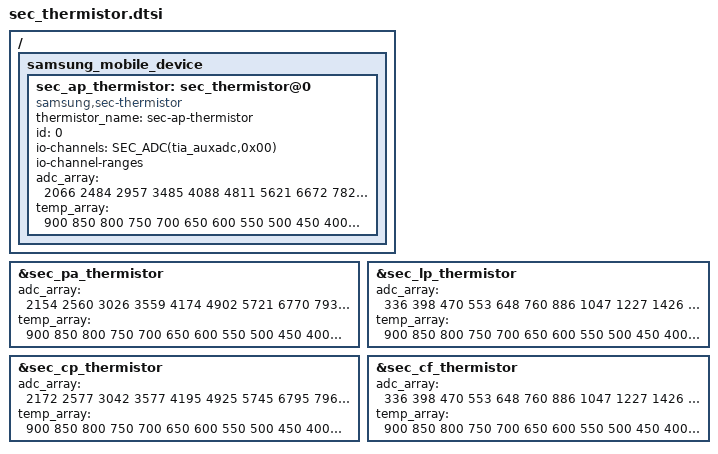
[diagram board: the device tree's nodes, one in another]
/ {
	fragment@smd {
		target-path = "/";
		__overlay__ {
			samsung_mobile_device {
				sec_ap_thermistor: sec_thermistor@0 {
					compatible = "samsung,sec-thermistor";
					status = "okay";
					thermistor_name = "sec-ap-thermistor";
					id = <0>;

					io-channels = SEC_ADC(tia_auxadc,0x00);
					io-channel-names = "ap_therm";
					io-channel-ranges;
				};
			};
		};
	};
};

/* /home/dpi/qb5_8814/workspace/P4_1716/android/kernel/kmodule/sec_pm/sec_thermistor/dts/sec_thermistor_mtk.a25ex_jpn.04.dtsi */
&sec_ap_thermistor {
	adc_array = <2066 2484 2957 3485 4088 4811 5621 6672 7826 9111
				10458 12043 13780 15592 17502 19410 21221 22944 24520 25952
				27175 28223 29079>;

	temp_array = <900 850 800 750 700 650 600 550 500 450
				400 350 300 250 200 150 100 50 0 (-50)
				(-100) (-150) (-200)>;
};

&sec_pa_thermistor {
	adc_array = <2154 2560 3026 3559 4174 4902 5721 6770 7934 9228
				10611 12203 13951 15771 17684 19593 21402 23108 24670 26088
				27297 28331 29169>;

	temp_array = <900 850 800 750 700 650 600 550 500 450
				400 350 300 250 200 150 100 50 0 (-50)
				(-100) (-150) (-200)>;
};

&sec_cp_thermistor {
	adc_array = <2172 2577 3042 3577 4195 4925 5745 6795 7962 9259
				10643 12236 13984 15809 17719 19627 21436 23136 24697 26109
				27318 28349 29183>;

	temp_array = <900 850 800 750 700 650 600 550 500 450
				400 350 300 250 200 150 100 50 0 (-50)
				(-100) (-150) (-200)>;
};

&sec_lp_thermistor {
	adc_array = <336 398 470 553 648 760 886 1047 1227 1426
				1639 1884 2152 2432 2726 3019 3297 3557 3797 4013
				4132 4132 4132>;

	temp_array = <900 850 800 750 700 650 600 550 500 450
				400 350 300 250 200 150 100 50 0 (-50)
				(-100) (-150) (-200)>;
};

&sec_cf_thermistor {
	adc_array = <336 398 470 553 648 760 886 1047 1227 1426
				1639 1884 2152 2432 2726 3019 3297 3557 3797 4013 
				4132 4132 4132>;

	temp_array = <900 850 800 750 700 650 600 550 500 450
				400 350 300 250 200 150 100 50 0 (-50)
				(-100) (-150) (-200)>;
};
